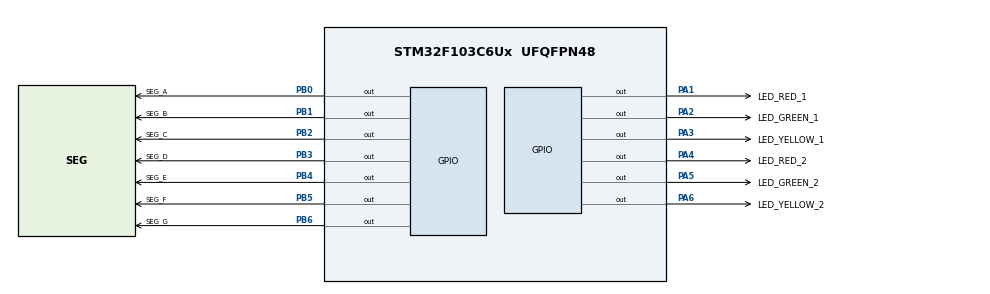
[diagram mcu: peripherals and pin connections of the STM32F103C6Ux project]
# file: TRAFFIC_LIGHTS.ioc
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Mcu.Family=STM32F1
Mcu.Name=STM32F103C6Ux
Mcu.Package=UFQFPN48
NVIC.PriorityGroup=NVIC_PRIORITYGROUP_4
PA1.GPIO_Label=LED_RED_1
PA1.Signal=GPIO_Output
PA2.GPIO_Label=LED_GREEN_1
PA2.Signal=GPIO_Output
PA3.GPIO_Label=LED_YELLOW_1
PA3.Signal=GPIO_Output
PA4.GPIO_Label=LED_RED_2
PA4.Signal=GPIO_Output
PA5.GPIO_Label=LED_GREEN_2
PA5.Signal=GPIO_Output
PA6.GPIO_Label=LED_YELLOW_2
PA6.Signal=GPIO_Output
PB0.GPIO_Label=SEG_A
PB0.Signal=GPIO_Output
PB1.GPIO_Label=SEG_B
PB1.Signal=GPIO_Output
PB2.GPIO_Label=SEG_C
PB2.Signal=GPIO_Output
PB3.GPIO_Label=SEG_D
PB3.Signal=GPIO_Output
PB4.GPIO_Label=SEG_E
PB4.Signal=GPIO_Output
PB5.GPIO_Label=SEG_F
PB5.Signal=GPIO_Output
PB6.GPIO_Label=SEG_G
PB6.Signal=GPIO_Output
ProjectManager.HeapSize=0x200
ProjectManager.StackSize=0x400
ProjectManager.TargetToolchain=STM32CubeIDE
RCC.APB1Freq_Value=8000000
RCC.APB2Freq_Value=8000000
VP_SYS_VS_ND.Mode=No_Debug
board=custom

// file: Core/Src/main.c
/* USER CODE BEGIN Header */
/**
  ******************************************************************************
  * @file           : main.c
  * @brief          : Main program body
  ******************************************************************************
  * @attention
  *
  * <h2><center>&copy; Copyright (c) 2024 STMicroelectronics.
  * All rights reserved.</center></h2>
  *
  * This software component is licensed by ST under BSD 3-Clause license,
  * the "License"; You may not use this file except in compliance with the
  * License. You may obtain a copy of the License at:
  *                        opensource.org/licenses/BSD-3-Clause
  *
  ******************************************************************************
  */
/* USER CODE END Header */
#include "main.h"

/* USER CODE BEGIN PV */
const uint8_t segmentPatterns[10] = {
    0b00111111, // 0: ABCDEF_
    0b00000110, // 1: __BC____
    0b01011011, // 2: AB_DEG__
    0b01001111, // 3: ABCD__G_
    0b01100110, // 4: _BC__FG_
    0b01101101, // 5: AB__D_F_
    0b01111101, // 6: ABCD_F__
    0b00000111, // 7: __BC____
    0b01111111, // 8: ABCDEFG_
    0b01101111  // 9: ABCD__G_
};
/* USER CODE END PV */

void SystemClock_Config(void);
static void MX_GPIO_Init(void);

/* USER CODE BEGIN 0 */
void display7SEG(int num);
/* USER CODE END 0 */

int main(void)
{

  /* MCU Configuration--------------------------------------------------------*/

  /* Reset of all peripherals, Initializes the Flash interface and the Systick. */
  HAL_Init();

  /* Configure the system clock */
  SystemClock_Config();

  /* Initialize all configured peripherals */
  MX_GPIO_Init();

  /* Infinite loop */
  /* USER CODE BEGIN WHILE */
  //int counter = 0;
  while (1)
  {
    /* USER CODE END WHILE */
	  //State 1
	      HAL_GPIO_WritePin(LED_RED_1_GPIO_Port, LED_RED_1_Pin, 1);
	  	  HAL_GPIO_WritePin(LED_RED_2_GPIO_Port, LED_RED_2_Pin, 0);

	  	  HAL_GPIO_WritePin(LED_GREEN_1_GPIO_Port, LED_GREEN_1_Pin, 0);
	  	  HAL_GPIO_WritePin(LED_GREEN_2_GPIO_Port, LED_GREEN_2_Pin, 1);
	  	  for(int i = 3; i > 0 ; i--){
	  		  display7SEG(i);
	  		  HAL_Delay(1000);
	  	  }
	  	  HAL_GPIO_WritePin(LED_GREEN_2_GPIO_Port, LED_GREEN_2_Pin, 0);

	  	  HAL_GPIO_WritePin(LED_YELLOW_1_GPIO_Port, LED_YELLOW_1_Pin, 0);
	  	  HAL_GPIO_WritePin(LED_YELLOW_2_GPIO_Port, LED_YELLOW_2_Pin, 1);
	  	  for(int i = 2; i > 0; i--){
	  		  display7SEG(i);
	  		  HAL_Delay(1000);
	  	  }
	  	  HAL_GPIO_WritePin(LED_YELLOW_2_GPIO_Port, LED_YELLOW_2_Pin, 0);

	      //State 2
	  	  HAL_GPIO_WritePin(LED_RED_1_GPIO_Port, LED_RED_1_Pin, 0);
	  	  HAL_GPIO_WritePin(LED_RED_2_GPIO_Port, LED_RED_2_Pin, 1);

	  	  HAL_GPIO_WritePin(LED_GREEN_1_GPIO_Port, LED_GREEN_1_Pin, 1);
	  	  HAL_GPIO_WritePin(LED_GREEN_2_GPIO_Port, LED_GREEN_2_Pin, 0);
	  	  for(int i = 3; i > 0; i--){
	  		  display7SEG(i);
	  		  HAL_Delay(1000);
	  	  }
	  	  HAL_GPIO_WritePin(LED_GREEN_1_GPIO_Port, LED_GREEN_1_Pin, 0);

	  	  HAL_GPIO_WritePin(LED_YELLOW_1_GPIO_Port, LED_YELLOW_1_Pin, 1);
	  	  HAL_GPIO_WritePin(LED_YELLOW_2_GPIO_Port, LED_YELLOW_2_Pin, 0);
	  	  for(int i = 2; i > 0; i--){
	  		  display7SEG(i);
	  		  HAL_Delay(1000);
	  	  }
	  	  HAL_GPIO_WritePin(LED_YELLOW_1_GPIO_Port, LED_YELLOW_1_Pin, 0);
  }
}

void display7SEG(int num) {
    if (num < 0 || num > 9) return; // Handle invalid input

    uint8_t pattern = segmentPatterns[num];

    HAL_GPIO_WritePin(SEG_A_GPIO_Port, SEG_A_Pin, (pattern & 0x01) ? 0 : 1);
    HAL_GPIO_WritePin(SEG_B_GPIO_Port, SEG_B_Pin, (pattern & 0x02) ? 0 : 1);
    HAL_GPIO_WritePin(SEG_C_GPIO_Port, SEG_C_Pin, (pattern & 0x04) ? 0 : 1);
    HAL_GPIO_WritePin(SEG_D_GPIO_Port, SEG_D_Pin, (pattern & 0x08) ? 0 : 1);
    HAL_GPIO_WritePin(SEG_E_GPIO_Port, SEG_E_Pin, (pattern & 0x10) ? 0 : 1);
    HAL_GPIO_WritePin(SEG_F_GPIO_Port, SEG_F_Pin, (pattern & 0x20) ? 0 : 1);
    HAL_GPIO_WritePin(SEG_G_GPIO_Port, SEG_G_Pin, (pattern & 0x40) ? 0 : 1);
}

void SystemClock_Config(void)
{
  RCC_OscInitTypeDef RCC_OscInitStruct = {0};
  RCC_ClkInitTypeDef RCC_ClkInitStruct = {0};

  /** Initializes the RCC Oscillators according to the specified parameters
  * in the RCC_OscInitTypeDef structure.
  */
  RCC_OscInitStruct.OscillatorType = RCC_OSCILLATORTYPE_HSI;
  RCC_OscInitStruct.HSIState = RCC_HSI_ON;
  RCC_OscInitStruct.HSICalibrationValue = RCC_HSICALIBRATION_DEFAULT;
  RCC_OscInitStruct.PLL.PLLState = RCC_PLL_NONE;
  if (HAL_RCC_OscConfig(&RCC_OscInitStruct) != HAL_OK)
  {
    Error_Handler();
  }
  /** Initializes the CPU, AHB and APB buses clocks
  */
  RCC_ClkInitStruct.ClockType = RCC_CLOCKTYPE_HCLK|RCC_CLOCKTYPE_SYSCLK
                              |RCC_CLOCKTYPE_PCLK1|RCC_CLOCKTYPE_PCLK2;
  RCC_ClkInitStruct.SYSCLKSource = RCC_SYSCLKSOURCE_HSI;
  RCC_ClkInitStruct.AHBCLKDivider = RCC_SYSCLK_DIV1;
  RCC_ClkInitStruct.APB1CLKDivider = RCC_HCLK_DIV1;
  RCC_ClkInitStruct.APB2CLKDivider = RCC_HCLK_DIV1;

  if (HAL_RCC_ClockConfig(&RCC_ClkInitStruct, FLASH_LATENCY_0) != HAL_OK)
  {
    Error_Handler();
  }
}

static void MX_GPIO_Init(void)
{
  GPIO_InitTypeDef GPIO_InitStruct = {0};

  /* GPIO Ports Clock Enable */
  __HAL_RCC_GPIOA_CLK_ENABLE();
  __HAL_RCC_GPIOB_CLK_ENABLE();

  /*Configure GPIO pin Output Level */
  HAL_GPIO_WritePin(GPIOA, LED_RED_1_Pin|LED_GREEN_1_Pin|LED_YELLOW_1_Pin|LED_RED_2_Pin
                          |LED_GREEN_2_Pin|LED_YELLOW_2_Pin, GPIO_PIN_RESET);

  /*Configure GPIO pin Output Level */
  HAL_GPIO_WritePin(GPIOB, SEG_A_Pin|SEG_B_Pin|SEG_C_Pin|SEG_D_Pin
                          |SEG_E_Pin|SEG_F_Pin|SEG_G_Pin, GPIO_PIN_RESET);

  /*Configure GPIO pins : LED_RED_1_Pin LED_GREEN_1_Pin LED_YELLOW_1_Pin LED_RED_2_Pin
                           LED_GREEN_2_Pin LED_YELLOW_2_Pin */
  GPIO_InitStruct.Pin = LED_RED_1_Pin|LED_GREEN_1_Pin|LED_YELLOW_1_Pin|LED_RED_2_Pin
                          |LED_GREEN_2_Pin|LED_YELLOW_2_Pin;
  GPIO_InitStruct.Mode = GPIO_MODE_OUTPUT_PP;
  GPIO_InitStruct.Pull = GPIO_NOPULL;
  GPIO_InitStruct.Speed = GPIO_SPEED_FREQ_LOW;
  HAL_GPIO_Init(GPIOA, &GPIO_InitStruct);

  /*Configure GPIO pins : SEG_A_Pin SEG_B_Pin SEG_C_Pin SEG_D_Pin
                           SEG_E_Pin SEG_F_Pin SEG_G_Pin */
  GPIO_InitStruct.Pin = SEG_A_Pin|SEG_B_Pin|SEG_C_Pin|SEG_D_Pin
                          |SEG_E_Pin|SEG_F_Pin|SEG_G_Pin;
  GPIO_InitStruct.Mode = GPIO_MODE_OUTPUT_PP;
  GPIO_InitStruct.Pull = GPIO_NOPULL;
  GPIO_InitStruct.Speed = GPIO_SPEED_FREQ_LOW;
  HAL_GPIO_Init(GPIOB, &GPIO_InitStruct);

}

void Error_Handler(void)
{
  __disable_irq();
  while (1)
  {
  }
}

/************************ (C) COPYRIGHT STMicroelectronics *****END OF FILE****/
